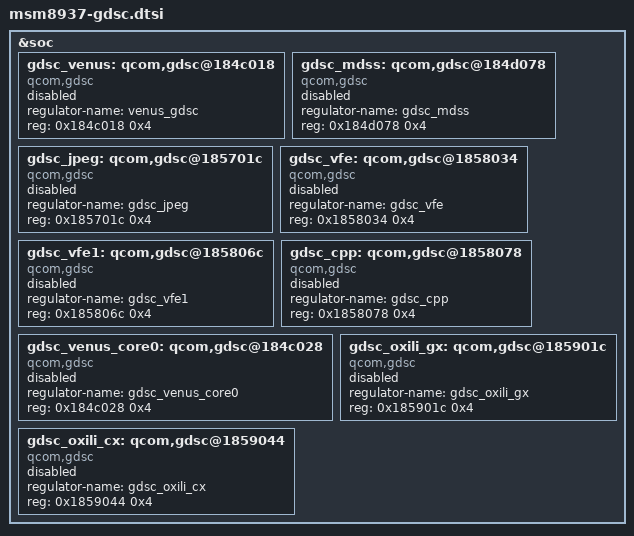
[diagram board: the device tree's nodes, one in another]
// SPDX-License-Identifier: GPL-2.0

&soc {
	gdsc_venus: qcom,gdsc@184c018 {
		compatible = "qcom,gdsc";
		regulator-name = "venus_gdsc";
		reg = <0x184c018 0x4>;
		status = "disabled";
	};

	gdsc_mdss: qcom,gdsc@184d078 {
		compatible = "qcom,gdsc";
		regulator-name = "gdsc_mdss";
		reg = <0x184d078 0x4>;
		status = "disabled";
	};

	gdsc_jpeg: qcom,gdsc@185701c {
		compatible = "qcom,gdsc";
		regulator-name = "gdsc_jpeg";
		reg = <0x185701c 0x4>;
		status = "disabled";
	};

	gdsc_vfe: qcom,gdsc@1858034 {
		compatible = "qcom,gdsc";
		regulator-name = "gdsc_vfe";
		reg = <0x1858034 0x4>;
		status = "disabled";
	};

	gdsc_vfe1: qcom,gdsc@185806c {
		compatible = "qcom,gdsc";
		regulator-name = "gdsc_vfe1";
		reg = <0x185806c 0x4>;
		status = "disabled";
	};

	gdsc_cpp: qcom,gdsc@1858078 {
		compatible = "qcom,gdsc";
		regulator-name = "gdsc_cpp";
		reg = <0x1858078 0x4>;
		status = "disabled";
	};

	gdsc_venus_core0: qcom,gdsc@184c028 {
		compatible = "qcom,gdsc";
		regulator-name = "gdsc_venus_core0";
		reg = <0x184c028 0x4>;
		status = "disabled";
	};

	gdsc_oxili_gx: qcom,gdsc@185901c {
		compatible = "qcom,gdsc";
		regulator-name = "gdsc_oxili_gx";
		reg = <0x185901c 0x4>;
		status = "disabled";
	};

	gdsc_oxili_cx: qcom,gdsc@1859044 {
		compatible = "qcom,gdsc";
		regulator-name = "gdsc_oxili_cx";
		reg = <0x1859044 0x4>;
		status = "disabled";
	};
};
